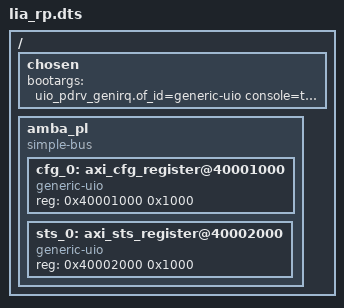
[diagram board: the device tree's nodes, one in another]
/include/ "system.dts"

/ {
  chosen {
    bootargs = "uio_pdrv_genirq.of_id=generic-uio console=ttyPS0,115200 root=/dev/mmcblk0p2 ro rootfstype=ext4 earlyprintk rootwait";
  };

  amba_pl: amba_pl {
    #address-cells = <1>;
    #size-cells = <1>;
    compatible = "simple-bus";
    ranges ;
    cfg_0: axi_cfg_register@40001000 {
      compatible = "generic-uio";
      reg = <0x40001000 0x1000>;
    };
    sts_0: axi_sts_register@40002000 {
      compatible = "generic-uio";
      reg = <0x40002000 0x1000>;
    };
  };
};

